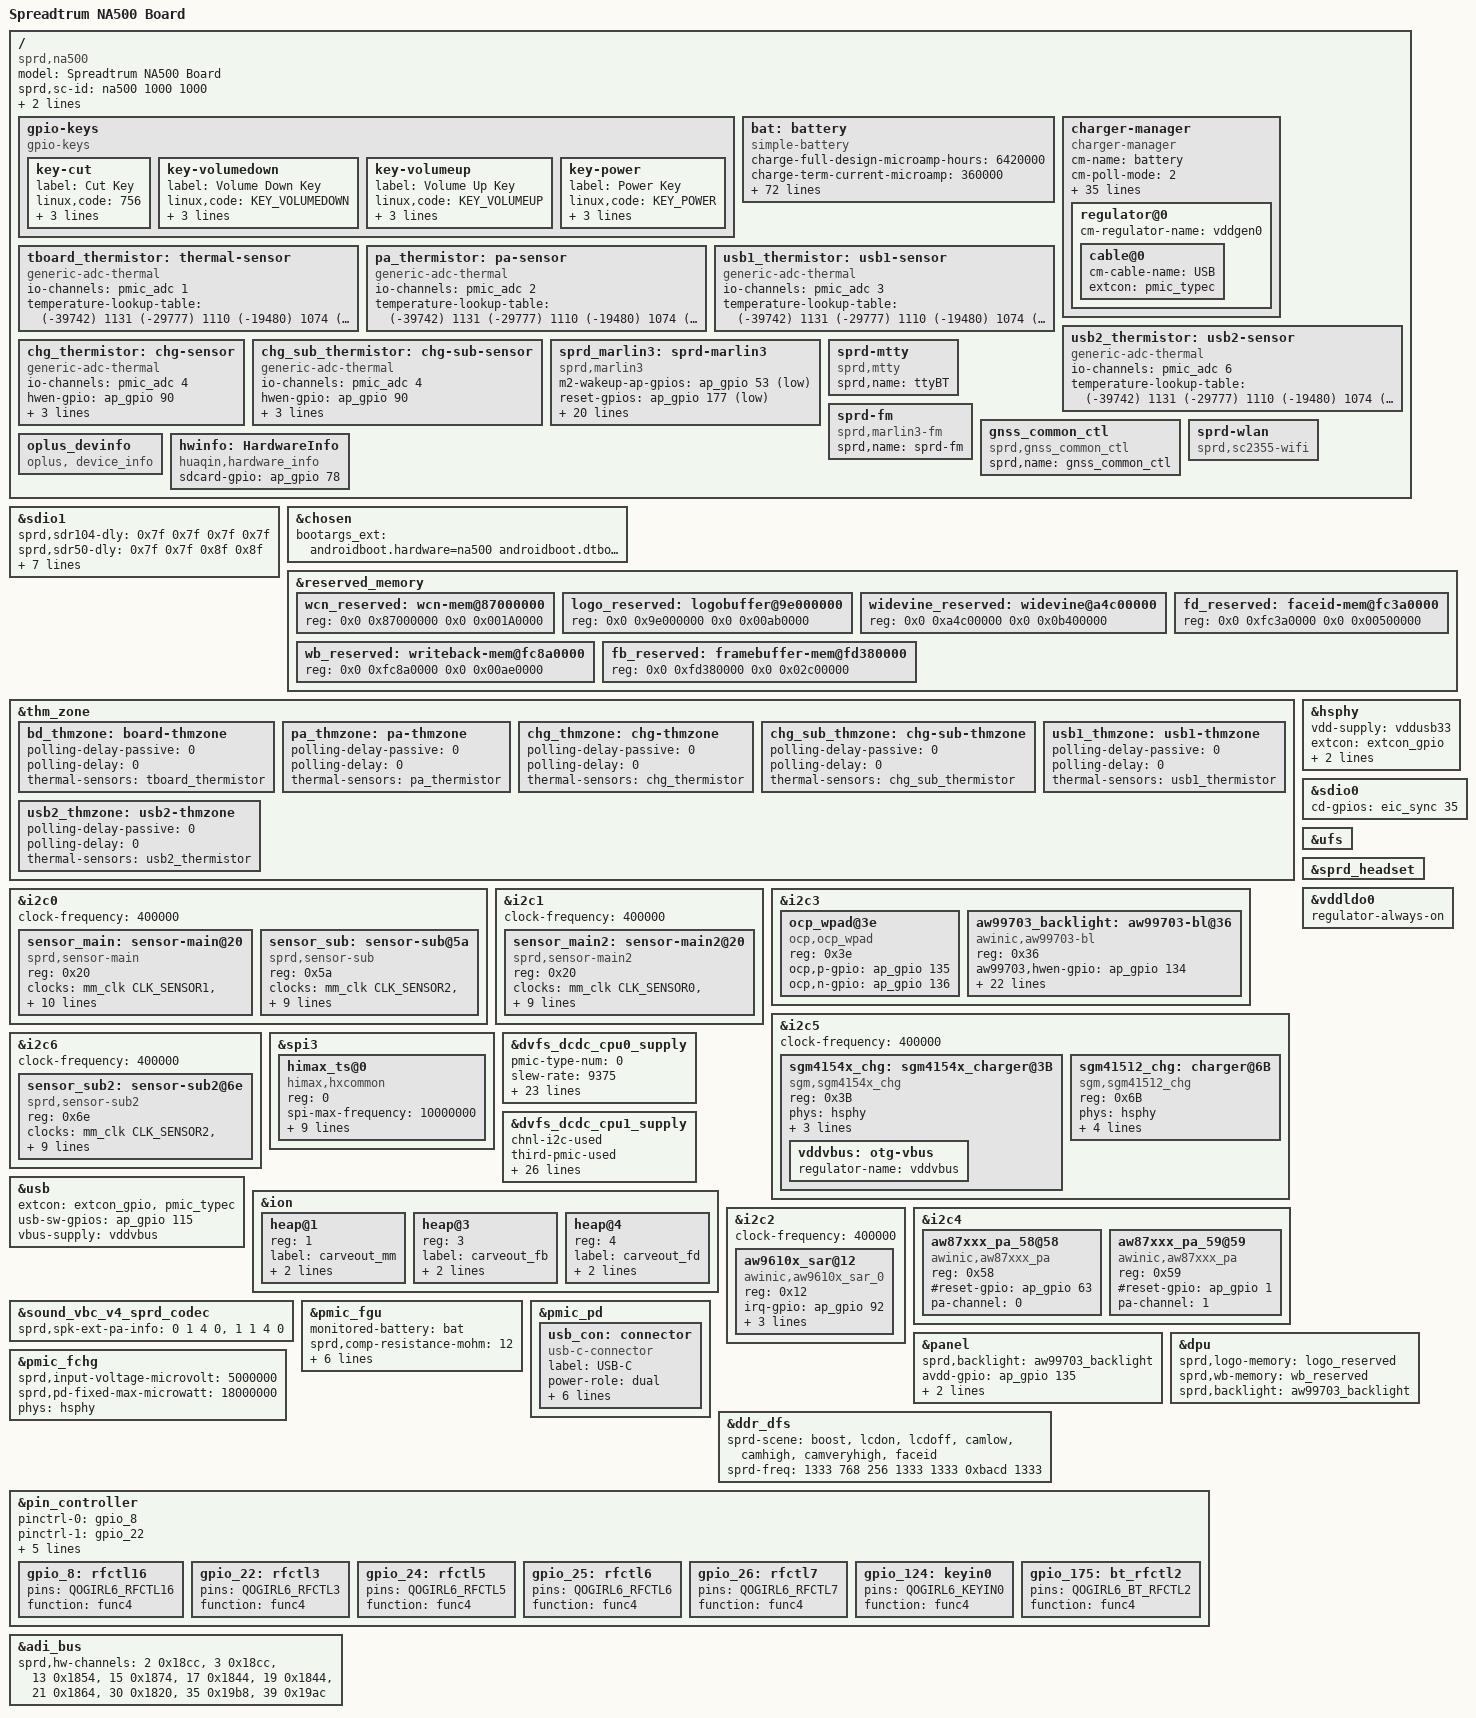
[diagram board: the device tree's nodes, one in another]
/dts-v1/;
/plugin/;
#include <dt-bindings/input/input.h>
#include <dt-bindings/gpio/gpio.h>
#include <dt-bindings/clock/sprd,ums9230-clk.h>
#include <dt-bindings/mfd/sprd,sc2730-regs.h>
#include <dt-bindings/mfd/sprd,sc2730-mask.h>
#include <dt-bindings/usb/pd.h>
/*#include "lcd/lcd_g40396_truly_mipi_fhd.dtsi"*/
#include "lcd/lcd_hx83102e_hsd_fy_mipi_hd.dtsi"
#include "lcd/lcd_ft8201ab_qc_mipi_hd.dtsi"
#include "lcd/lcd_nt36523_lc_mipi_hd.dtsi"
#include "lcd/lcd_hx83102e_hsd_mipi_hd.dtsi"
#include "lcd/lcd_dummy_mipi.dtsi"
//#include "battery/NICKY_REALME_ATL_4V45_5000mah.dtsi"
//#include "battery/NICKY_REALME_GUANYU_4V45_5000mah.dtsi"

/ {

	model = "Spreadtrum NA500 Board";

	compatible = "sprd,na500";

	sprd,sc-id = "na500 1000 1000";
	sprd,dtsi_no = "137005";//2172D
	sprd,board_id = "EVB";

	fragment {
		target-path = "/";
		__overlay__ {
			/*pwm_backlight: sprd_backlight {
				compatible = "sprd,sharkl6-backlight";
				pwms = <&pwms 2 40000>;
				pwm-names = "backlight";
				sprd,max-brightness-level = <924>;
				default-brightness-level = <262>;
				sprd,brightness-scale = <1023>;
				brightness-levels = <
							  0   3   4   5   6   7
					  8   9  10  11  12  13  14  16  17  18
					 19  20  21  22  23  24  25  26  27  28
					 29  31  33  35  37  39  41  43  45  47
					 48  50  52  54  56  58  60  62  64  67
					 69  72  74  76  78  80  82  84  86  88
					 90  92  94  96  98 100 102 104 107 109
					112 114 116 118 120 122 124 126 128 130
					132 134 136 138 140 142 144 147 149 151
					154 156 158 160 162 164 166 168 170 172
					175 178 181 184 187 190 193 196 199 203
					205 208 211 214 217 220 223 226 229 234
					237 240 243 247 250 253 256 259 263 266
					269 270 274 277 280 283 287 290 294 297
					300 303 307 310 314 318 325 329 334 339
					340 343 347 350 354 358 365 369 374 380
					382 385 389 392 396 400 407 411 416 422
					426 430 434 438 442 446 452 457 460 464
					470 474 480 486 492 498 504 508 512 516
					522 527 532 536 540 545 550 555 561 568
					574 579 584 589 594 600 605 610 615 620
					625 630 635 641 647 652 657 662 667 673
					688 694 700 706 712 716 720 725 730 735
					740 746 752 758 764 770 776 782 790 798
					803 810 817 825 832 840 845 850 855 861
					866 872 878 884 890 896 903 911 918 924
				>;
			};
*/
			gpio-keys {
				compatible = "gpio-keys";

				key-cut {
					label = "Cut Key";
					linux,code = <756>;
					gpios = <&ap_gpio 166 GPIO_ACTIVE_HIGH>;
					debounce-interval = <2>;
					wakeup-source;
				};
				
				key-volumedown {
					label = "Volume Down Key";
					linux,code = <KEY_VOLUMEDOWN>;
					gpios = <&ap_gpio 124 GPIO_ACTIVE_LOW>;
					debounce-interval = <2>;
					wakeup-source;
				};

				key-volumeup {
					label = "Volume Up Key";
					linux,code = <KEY_VOLUMEUP>;
					gpios = <&pmic_eic 4 GPIO_ACTIVE_HIGH>;
					debounce-interval = <2>;
					wakeup-source;
				};

				key-power {
					label = "Power Key";
					linux,code = <KEY_POWER>;
					gpios = <&pmic_eic 1 GPIO_ACTIVE_LOW>;
					debounce-interval = <2>;
					wakeup-source;
				};
			};

			bat: battery {
				compatible = "simple-battery";
				charge-full-design-microamp-hours = <6420000>;
				charge-term-current-microamp = <360000>;
				constant_charge_voltage_max_microvolt = <4432000>;
				factory-internal-resistance-micro-ohms = <94000>;
				voltage-min-design-microvolt = <3455000>;
				fast-charge-threshold-microvolt = <4200000>;
				ocv-capacity-celsius = <20>;
				ocv-capacity-table-0 = <4405000 100>, <4342000 95>, <4283000 90>,
							<4222000 85>, <4162000 80>, <4104000 75>,
							<4051000 70>, <4002000 65>, <3957000 60>,
							<3906000 55>, <3860000 50>, <3832000 45>,
							<3811000 40>, <3795000 35>, <3781000 30>,
							<3766000 25>, <3746000 20>, <3723000 15>,
							<3691000 10>, <3678000 5>, <3400000 0>;
				voltage-temp-table = <1404493 650>, <1307739 700>, <1203814 750>,
							<1095466 800>, <986112 850>, <878559 900>,
							<775113 950>, <678461 1000>, <590240 1050>,
							<510773 1100>, <440156 1150>, <378279 1200>,
							<324561 1250>, <278079 1300>, <238259 1350>,
							<204266 1400>, <175208 1450>, <150459 1500>,
							<129410 1550>, <111497 1600>, <96484 1650>,
							<83710 1700>, <72772 1750>, <63417 1800>,
							<55293 1850>, <49524 1900>, <43352 1950>;
				capacity-temp-table = <45 98>, <25 100>, <10 96>, <0 86>, <(-10) 80>;
				resistance-temp-table = <45 77>, <25 100>, <10 156>, <0 1207>, <(-10) 1257>;
				charge-sdp-current-microamp = <600000 500000>;
				charge-dcp-current-microamp = <2090000 2100000>;
				charge-cdp-current-microamp = <1520000 1500000>;
				charge-unknown-current-microamp = <2000000 2000000>;
				charge-fchg-current-microamp = <3000000 2000000>; /*1700 1000*/
				cm-dcp-jeita-temp-table = <900 920 0 4432000 0 4180000>,
					<1000 980 0 4435000 0 4180000>,
					<1050 1030 2090000 4432000 1520000 4180000>,
					<1120 1100 2090000 4432000 1520000 4180000>,
					<1160 1140 2090000 4432000 2090000 4432000>,
					<1450 1430 2090000 4432000 2090000 4432000>,
					<1530 1510 1520000 4128000 1520000 4128000>;
				cm-sdp-jeita-temp-table = <900 920 0 4432000 0 4180000>,
					<1000 980 0 4432000 0 4180000>,
					<1050 1030 600000 4432000 600000 4432000>,
					<1120 1100 600000 4432000 600000 4432000>,
					<1160 1140 600000 4432000 600000 4432000>,
					<1450 1430 600000 4432000 600000 4432000>,
					<1530 1510 600000 4128000 600000 4128000>;
				cm-cdp-jeita-temp-table = <900 920 0 4432000 0 4180000>,
					<1000 980 0 4432000 0 4180000>,
					<1050 1030 1520000 4432000 1520000 4432000>,
					<1120 1100 1520000 4432000 1520000 4432000>,
					<1160 1140 1520000 4432000 1520000 4432000>,
					<1450 1430 1520000 4432000 1520000 4432000>,
					<1530 1510 1520000 4128000 1520000 4128000>;
				cm-unknown-jeita-temp-table = <900 920 0 4432000 0 4180000>,
					<1000 980 0 4432000 0 4180000>,
					<1050 1030 2000000 4432000 1520000 4180000>,
					<1120 1100 2000000 4432000 1520000 4180000>,
					<1160 1140 2000000 4432000 2000000 4432000>,
					<1450 1430 2000000 4432000 2000000 4432000>,
					<1530 1510 1520000 4128000 1520000 4128000>;
				cm-fchg-jeita-temp-table =<900 920 0 4432000 0 4180000>,
					<1000 980 0 4432000 0 4180000>,
					<1050 1030 2565000 4432000 1710000 4180000>,
					<1120 1100 2565000 4432000 1710000 4180000>,
					<1160 1140 3000000 4432000 3000000 4432000>,
					<1450 1430 3000000 4432000 3000000 4432000>,
					<1530 1510 1520000 4128000 1520000 4128000>;
			};

			charger-manager {
				compatible = "charger-manager";
				cm-name = "battery";
				cm-poll-mode = <2>;
				cm-poll-interval = <5000>;
				cm-battery-stat = <2>;

				cm-fullbatt-vchkdrop-ms = <30000>;
				cm-fullbatt-vchkdrop-volt = <100000>;
				cm-fullbatt-voltage = <4410000>;
				cm-fullbatt-current = <360000>;
				cm-fullbatt-capacity = <100>;
				/*Charge pump target charge current*/
				cm-cp-taper-current = <1000000>;

				cm-num-chargers = <2>;
				cm-num-fast-chargers = <1>;
				cm-chargers = "sgm4154x_charger", "sgm41512_charger";
				cm-fast-chargers = "sc2730_fast_charger";
				cm-fuel-gauge = "sc27xx-fgu";

				/* in deci centigrade */
				cm-battery-cold = <200>;
				cm-battery-cold-in-minus;
				cm-battery-hot = <800>;
				cm-battery-temp-diff = <100>;

				/* Allow charging for 25.6hr */
				cm-charging-max = <92160000>;
				/* recovery charging after stop charging 45min */
				cm-discharging-max = <2700000>;

				/* the interval to feed charger watchdog */
				cm-wdt-interval = <60>;

				/* drop voltage in microVolts to allow shutdown */
				cm-shutdown-voltage = <3350000>;

				/* when 99% of the time is exceeded, it will be forced to 100% */
				cm-tickle-time-out = <580>;

				/* how much time to allow capacity change */
				cm-one-cap-time = <30>;
				/* cm-thermal-zone = "board-thmzone"; */
				cm-usb1-zone = "usb1-thmzone";
				cm-usb2-zone = "usb2-thmzone";
				/* when the safe charging voltage is exceeded, stop charging */
				cm-charge-voltage-max = <5800000>;
				cm-fast-charge-voltage-max = <10000000>;
				cm-double-ic-total-limit-current = <2000000>;

				/* drop voltage in microVolts to restart charging */
				cm-charge-voltage-drop = <0>;
				cm-fast-charge-voltage-drop = <700000>;
				cm-flash-charge-voltage-drop = <1000000>;

				//cm-cap-remap-table = <1 2 3>, <2 3 2>, <98 99 2>, <99 100 3>;

				monitored-battery = <&bat>;
				cm-capacity-track;
				
/*odm.hq.bsp.luowenjiang@huaqin.com 2021.11.04 modify for  usb temp protection star*/				
				cm-charge-gpio = <&ap_gpio 113 0>;
/*odm.hq.bsp.luowenjiang@huaqin.com 2021.11.04 modify for  usb temp protection end*/

//				cm-ir-cv-offset-microvolt = <100000>;
//				cm-ir-rc = <10>;
//				cm-ir-us-upper-limit-microvolt = <4500000>;

				regulator@0 {
					cm-regulator-name = "vddgen0";
					cable@0 {
						cm-cable-name = "USB";
						extcon = <&pmic_typec>;
					};
				};
			};

			tboard_thermistor: thermal-sensor {
				compatible = "generic-adc-thermal";
				#thermal-sensor-cells = <0>;
				io-channels = <&pmic_adc 1>;
				io-channel-names = "sensor-channel";
				temperature-lookup-table = <
					(-39742) 1131
					(-29777) 1110
					(-19480) 1074
					(-4679) 983
					10110 838
					24805 654
					44922 413
					54903 316
					64895 238
					74884 178
					84883 133
					94883 100
					104880 75
					114889 57
					124872 43 >;
			};

			pa_thermistor: pa-sensor {
				compatible = "generic-adc-thermal";
				#thermal-sensor-cells = <0>;
				io-channels = <&pmic_adc 2>;
				io-channel-names = "sensor-channel";
				temperature-lookup-table = <
					(-39742) 1131
					(-29777) 1110
					(-19480) 1074
					(-4679) 983
					10110 838
					24805 654
					44922 413
					54903 316
					64895 238
					74884 178
					84883 133
					94883 100
					104880 75
					114889 57
					124872 43 >;
			};
			usb1_thermistor: usb1-sensor {
				compatible = "generic-adc-thermal";
				#thermal-sensor-cells = <0>;
				io-channels = <&pmic_adc 3>;
				io-channel-names = "sensor-channel";
				temperature-lookup-table = <
					(-39742) 1131
					(-29777) 1110
					(-19480) 1074
					(-4679) 983
					10110 838
					24805 654
					44922 413
					54903 316
					64895 238
					74884 178
					84883 133
					94883 100
					104880 75
					114889 57
					124872 43 >;
			};
			usb2_thermistor: usb2-sensor {
				compatible = "generic-adc-thermal";
				#thermal-sensor-cells = <0>;
				io-channels = <&pmic_adc 6>;
				io-channel-names = "sensor-channel";
				temperature-lookup-table = <
					(-39742) 1131
					(-29777) 1110
					(-19480) 1074
					(-4679) 983
					10110 838
					24805 654
					44922 413
					54903 316
					64895 238
					74884 178
					84883 133
					94883 100
					104880 75
					114889 57
					124872 43 >;
			};

			chg_thermistor: chg-sensor {
				compatible = "generic-adc-thermal";
				#thermal-sensor-cells = <0>;
				io-channels = <&pmic_adc 4>;
				io-channel-names = "sensor-channel";
				hwen-gpio = <&ap_gpio 90 0>;
				hwen-channel = <0>;
				temperature-lookup-table = <
					(-39742) 1131
					(-29777) 1110
					(-19480) 1074
					(-4679) 983
					10110 838
					24805 654
					44922 413
					54903 316
					64895 238
					74884 178
					84883 133
					94883 100
					104880 75
					114889 57
					124872 43 >;
			};
			
			chg_sub_thermistor: chg-sub-sensor {
				compatible = "generic-adc-thermal";
				#thermal-sensor-cells = <0>;
				io-channels = <&pmic_adc 4>;
				io-channel-names = "sensor-channel";
				hwen-gpio = <&ap_gpio 90 0>;
				hwen-channel = <1>;
				temperature-lookup-table = <
					(-39742) 1131
					(-29777) 1110
					(-19480) 1074
					(-4679) 983
					10110 838
					24805 654
					44922 413
					54903 316
					64895 238
					74884 178
					84883 133
					94883 100
					104880 75
					114889 57
					124872 43 >;
			};
			sprd_marlin3: sprd-marlin3 {
				compatible = "sprd,marlin3";
				m2-wakeup-ap-gpios = <&ap_gpio 53 GPIO_ACTIVE_LOW>;
				reset-gpios = <&ap_gpio 177 GPIO_ACTIVE_LOW>;
				enable-gpios = <&ap_gpio 116 GPIO_ACTIVE_LOW>;
				m2-to-ap-irq-gpios = <&ap_gpio 52 GPIO_ACTIVE_LOW>;
				avdd12-supply = <&vddwcn>;
				avdd33-supply = <&vddwifipa>;
				dcxo18-supply = <&vddsim2>;

				clock-names = "clk_32k","source","enable";
				clocks = <&aon_clk CLK_AUX2>,
					 <&ext_32k>,
					 <&aonapb_gate CLK_AUX2_EB>;

				reg = <0 0x87000000 0 0x00100000>,
					<0 0x87100000 0 0xA0000>;
				reg-names = "btwf_mem", "gnss_mem";

				sdhci-name = <&sdio1>;
				sprd,btwf-file-name = "/dev/block/by-name/wcnmodem";
				sprd,gnss-file-name = "/dev/block/by-name/gnssmodem";
				adma-tx;
				adma-rx;

				/*
				 * bound parameter:
				 * [0]:addr offset, [1]:mask, [2]:unboundval, [3]:boundval
				 */
				/* avdd12-parent-bound-chip = <REG_ANA_SLP_DCDC_PD_CTRL MASK_ANA_SLP_DCDCGEN1_PD_EN 0x0 MASK_ANA_SLP_DCDCGEN1_PD_EN>; */
				avdd12-bound-wbreq = <REG_ANA_LDO_XTL_EN10 MASK_ANA_LDO_VDDWCN_EXT_XTL3_EN 0x0 MASK_ANA_LDO_VDDWCN_EXT_XTL3_EN>;
				avdd33-bound-wbreq = <REG_ANA_LDO_XTL_EN11 MASK_ANA_LDO_VDDWIFIPA_EXT_XTL3_EN 0x0 MASK_ANA_LDO_VDDWIFIPA_EXT_XTL3_EN>;
			};

			sprd-mtty {
				compatible = "sprd,mtty";
				sprd,name = "ttyBT";
			};

			sprd-fm {
				compatible = "sprd,marlin3-fm";
				sprd,name = "sprd-fm";
			};

			gnss_common_ctl {
				compatible = "sprd,gnss_common_ctl";
				sprd,name = "gnss_common_ctl";
			};

			sprd-wlan{
				compatible = "sprd,sc2355-wifi";
			};
			/*Used to show hardware information for oplus factory mode*/
			oplus_devinfo:oplus_devinfo {
				compatible = "oplus, device_info";
				status = "okay";
			};
			/*Used to show hardware information for hq factory mode*/
			hwinfo:HardwareInfo {
				compatible = "huaqin,hardware_info";
				sdcard-gpio = <&ap_gpio 78 0>;
				status = "okay";
			};
		};
	};
};

&sdio1 {
	sprd,sdr104-dly = <0x7f 0x7f 0x7f 0x7f>;
	sprd,sdr50-dly = <0x7f 0x7f 0x8f 0x8f>;
	sd-uhs-sdr104;
	sd-uhs-sdr50;
	bus-width = <4>;
	sprd,name = "sdio_wifi";
	sprd,sdio-adma;
	no-sd;
	no-mmc;
	status = "okay";
};

&chosen {
	bootargs_ext = "androidboot.hardware=na500 androidboot.dtbo_idx=0";
};

&reserved_memory {
	wcn_reserved: wcn-mem@87000000 {
		reg = <0x0 0x87000000 0x0 0x001A0000>;
	};

	logo_reserved: logobuffer@9e000000{
		reg = <0x0 0x9e000000 0x0 0x00ab0000>;
	};

	widevine_reserved: widevine@a4c00000 {
        reg = <0x0 0xa4c00000 0x0 0x0b400000>;
    };

	fd_reserved: faceid-mem@fc3a0000 {
		reg = <0x0 0xfc3a0000 0x0 0x00500000>;
	};

	wb_reserved: writeback-mem@fc8a0000 {
		reg = <0x0 0xfc8a0000 0x0 0x00ae0000>;
	};

	fb_reserved: framebuffer-mem@fd380000 {
		reg = <0x0 0xfd380000 0x0 0x02c00000>;
	};
};

&thm_zone {
	bd_thmzone: board-thmzone {
		polling-delay-passive = <0>;
		polling-delay = <0>;
		thermal-sensors = <&tboard_thermistor>;
	};

	pa_thmzone: pa-thmzone {
		polling-delay-passive = <0>;
		polling-delay = <0>;
		thermal-sensors = <&pa_thermistor>;
	};

	chg_thmzone: chg-thmzone {
		polling-delay-passive = <0>;
		polling-delay = <0>;
		thermal-sensors = <&chg_thermistor>;
	};
	chg_sub_thmzone: chg-sub-thmzone {
		polling-delay-passive = <0>;
		polling-delay = <0>;
		thermal-sensors = <&chg_sub_thermistor>;
	};

	usb1_thmzone: usb1-thmzone {
		polling-delay-passive = <0>;
		polling-delay = <0>;
		thermal-sensors = <&usb1_thermistor>;
	};
	usb2_thmzone: usb2-thmzone {
		polling-delay-passive = <0>;
		polling-delay = <0>;
		thermal-sensors = <&usb2_thermistor>;
	};
};

&i2c0 {
	status = "okay";
	clock-frequency = <400000>;

	sensor_main: sensor-main@20 {
		compatible = "sprd,sensor-main";
		reg = <0x20>;
		clock-names = "clk_src","sensor_eb",
			"clk_96m","clk_76m8",
			"clk_48m","clk_26m";
		clocks = <&mm_clk CLK_SENSOR1>,<&mm_gate CLK_MM_SENSOR1_EB>,
				<&pll1 CLK_TWPLL_96M>,<&pll1 CLK_TWPLL_76M8>,
				<&pll1 CLK_TWPLL_48M>,<&ext_26m>;
		vddio-supply = <&vddcamio>;
		vddcamd-supply = <&vddcamd0>;
		vddcama-supply = <&vddcama1>;
		//avdd-gpios = <&ap_gpio 129 0>;
		vddcammot-supply = <&vddcammot>;
		reset-gpios = <&ap_gpio 45 0>;
        //power-down-gpios = <&ap_gpio 47 0>;
		sprd,phyid = <0>;
		csi = <&csi0>;
	};

	sensor_sub: sensor-sub@5a {
		compatible = "sprd,sensor-sub";
		reg = <0x5a>;
		clock-names = "clk_src","sensor_eb",
			"clk_96m","clk_76m8",
			"clk_48m","clk_26m";
		clocks = <&mm_clk CLK_SENSOR2>,<&mm_gate CLK_MM_SENSOR2_EB>,
				<&pll1 CLK_TWPLL_96M>,<&pll1 CLK_TWPLL_76M8>,
				<&pll1 CLK_TWPLL_48M>,<&ext_26m>;
		vddio-supply = <&vddcamio>;
		vddcama-supply = <&vddcama0>;
		//avdd-gpios = <&ap_gpio 138 0>;
		vddcamd-supply = <&vddcamd1>;
		reset-gpios = <&ap_gpio 44 0>;
		sprd,phyid = <5>;
		csi = <&csi0>;
	};
};

&i2c1 {
	status = "okay";
	clock-frequency = <400000>;

	sensor_main2: sensor-main2@20 {
		compatible = "sprd,sensor-main2";
		reg = <0x20>;
		clock-names = "clk_src","sensor_eb",
			"clk_96m","clk_76m8",
			"clk_48m","clk_26m";
		clocks = <&mm_clk CLK_SENSOR0>,<&mm_gate CLK_MM_SENSOR0_EB>,
				<&pll1 CLK_TWPLL_96M>,<&pll1 CLK_TWPLL_76M8>,
				<&pll1 CLK_TWPLL_48M>,<&ext_26m>;
		vddio-supply = <&vddcamio>;
		vddcama-supply = <&vddcama1>;
	/*	vddcamd-supply = <&vddcamd0>;*/
	/*	vddcammot-supply = <&vddcammot>;*/
	/*	mot-gpios = <&ap_gpio 113 0>;*/
		reset-gpios = <&ap_gpio 41 0>;
		power-down-gpios = <&ap_gpio 46 0>;
	/*	mipi-switch-en-gpios = <&ap_gpio 55 0>;*/
	/*	mipi-switch-mode-gpios = <&ap_gpio 8 0>;*/
		sprd,phyid = <3>;
		csi = <&csi1>;
	};


};



&i2c3 {
	ocp_wpad@3e {
		compatible = "ocp,ocp_wpad";
		reg = <0x3e>;
		ocp,p-gpio = <&ap_gpio 135 0>;
		ocp,n-gpio = <&ap_gpio 136 0>;
	};


	aw99703_backlight:aw99703-bl@36 {
		compatible = "awinic,aw99703-bl";
		reg = <0x36>;
		aw99703,hwen-gpio = <&ap_gpio 134 0>;
		/* brightness map level 1:256,2:1024,3:2048 */
		aw99703,bl-map = <3>;
		aw99703,using-lsb;
		aw99703,ovp-level = <3>; /* 38V(default) */
		aw99703,ocp-level = <2>; /* 2.7A(default) */
		aw99703,switch-freq = <1>; /* 1000kHz(default) */
		aw99703,auto-freq-high = <0x80>;
		aw99703,auto-freq-low = <0x10>;
		aw99703,bl-fscal-led = <0x13>; /* 20mA(default) */
		aw99703,bl-channel = <3>;
		aw99703,turn-on-ramp = <0x04>; /* 8ms(default) */
		aw99703,turn-off-ramp = <0x04>; /* 8ms(default) */
		aw99703,pwm-trans-dim = <0>; /* 2ms(default) */
		aw99703,i2c-trans-dim = <0>; /* 1us(default) */
		aw99703,pwm-mode = <1>; /* 0 pwm enable,1 PWM disable */
		aw99703,map-type = <0>; /* linear */
		aw99703,work-mode = <1>; /* backlight */
		aw99703,flash-timeout-time = <0x05>; /* 500ms(default) */
		aw99703,flash-current = <0x08>; /* 59.2mA(default) */
		aw99703,efuse-config = <0x1C 0x61 0x61 0x4C 0x2C 0xC0 0x08 0x00 0x01 0xC0 0x00 0x00 0x50>;
				brightness-levels = <
					2
					4 6 8 10 12  14  16  18  20  22  24  26  28  30  32  34  36  38  
					40  42  44  46  48  50  52  54  56  58  
					60  62  64  66  68  71  74  77  80  83  
					86  89  92  95  98  101  104  107  110  113  
					116  120  124  128  134  138  144  148  152  156  
					160  164  168  172  176  180  184  188  192  196  
					200  204  208  214  218  224  228  232  236  240  
					244  248  252  256  260  264  268  272  276  280  
					284  288  294  298  302  308  312  316  320  324  
					328  332  336  340  344  350  356  362  368  374  
					380  386  392  398  406  410  416  422  428  434  
					440  446  452  458  468  474  480  486  494  500  
					506  512  518  526  532  538  540  548  554  560  
					566  574  580  588  594  600  606  614  620  628  
					636  650  658  668  678  680  686  694  700  708  
					716  730  738  748  760  764  770  778  784  792  
					800  814  822  832  844  852  860  868  876  884  
					892  904  914  920  928  940  948  960  972  984  
					996  1008  1016  1024  1032  1044  1054  1064  1072  1080  
					1090  1100  1110  1122  1136  1148  1158  1168  1178  1188  
					1200  1210  1220  1230  1240  1250  1260  1270  1282  1294  
					1304  1314  1324  1334  1346  1376  1388  1400  1412  1424  
					1432  1440  1450  1460  1470  1480  1492  1504  1516  1528  
					1540  1552  1564  1580  1596  1606  1620  1638
				>;
		status = "ok";
	};
};

&i2c5 {
	status = "okay";
	clock-frequency = <400000>;

	sgm4154x_chg: sgm4154x_charger@3B {
		compatible = "sgm,sgm4154x_chg";
		reg = <0x3B>;
		phys = <&hsphy>;
		monitored-battery = <&bat>;
		extcon = <&pmic_typec>;
		pd-extcon-enable;
		vddvbus:otg-vbus {
			regulator-name = "vddvbus";
		};
	};

	sgm41512_chg: charger@6B {
		compatible = "sgm,sgm41512_chg";
		reg = <0x6B>;
		phys = <&hsphy>;
		monitored-battery = <&bat>;
		extcon = <&pmic_typec>;
		enable-gpio = <&ap_gpio 130 GPIO_ACTIVE_LOW>;
		role-slave;
	};

};

&i2c6 {
	status = "okay";
	clock-frequency = <400000>;

	sensor_sub2: sensor-sub2@6e {
		compatible = "sprd,sensor-sub2";
		reg = <0x6e>;
		clock-names = "clk_src","sensor_eb",
			"clk_96m","clk_76m8",
			"clk_48m","clk_26m";
		clocks = <&mm_clk CLK_SENSOR2>,<&mm_gate CLK_MM_SENSOR2_EB>,
			<&pll1 CLK_TWPLL_96M>,<&pll1 CLK_TWPLL_76M8>,
			<&pll1 CLK_TWPLL_48M>,<&ext_26m>;
		vddio-supply = <&vddcamio>;
		avdd-gpios = <&ap_gpio 137 0>;
		vddcamd-supply = <&vddcamd1>;
		vddcammot-supply = <&vddcammot>;
	/*	mot-gpios = <&ap_gpio 112 0>;
		reset-gpios = <&ap_gpio 114 0>;
		power-down-gpios = <&ap_gpio 40 0>;*/
		sprd,phyid = <3>;
		csi = <&csi2>;
	};
};



&spi3 {
	status = "okay";

	himax_ts@0 {
	compatible = "himax,hxcommon","focaltech,fts";
	reg = <0>;
	spi-max-frequency = <10000000>;

	himax,panel-coords = <0 800 0 1340>;
	himax,display-coords = <0 800 0 1340>;
	/*himax,irq-gpio = <&ap_gpio 144 GPIO_ACTIVE_HIGH>;*/
	himax,irq-gpio = <&eic_async 16 GPIO_ACTIVE_HIGH>;
	himax,rst-gpio = <&ap_gpio 145 GPIO_ACTIVE_HIGH>;
	report_type = <1>;
	
	/*focaltech,irq-gpio = <&ap_gpio 144 0>;*/
	focaltech,irq-gpio = <&eic_async 16 GPIO_ACTIVE_HIGH>;
	focaltech,reset-gpio = <&ap_gpio 145 0>;
	focaltech,max-touch-number = <10>;
	focaltech,display-coords =  <0 0 800 1340>;	
	};
};

&dvfs_dcdc_cpu0_supply {
	pmic-type-num = <0>;
	slew-rate = <9375>; /* 9375uV/us */
	top-dvfs-adi-state = <0x70 0 0xf>;
	voltage-grade-num = <8>;
	voltage-grade = <0 0xf0 0xf4 0 0x1ff>,
		<1 0xf0 0xf4 9 0x1ff>,
		<2 0x100 0xf4 18 0x1ff>,
		<3 0x110 0xf8 0 0x1ff>,
		<4 0x120 0xf8 9 0x1ff>,
		<5 0x130 0xf8 18 0x1ff>,
		<6 0x140 0xfc 0 0x1ff>,
		<7 0x140 0xfc 9 0x1ff>;
	voltage-up-delay = <50 0x58 0 0xffff 0x600>,
		<100 0x58 16 0xffff 0xa00>,
		<150 0x54 0 0xffff 0xf00>,
		<200 0x54 16 0xffff 0x1400>,
		<250 0x50 0 0xffff 0x1900>,
		<300 0x50 16 0xffff 0x1e00>,
		<350 0x110 0 0xffff 0x2300>;
	voltage-down-delay = <50 0x64 0 0xffff 0x600>,
		<100 0x64 16 0xffff 0xa00>,
		<150 0x60 0 0xffff 0xf00>,
		<200 0x60 16 0xffff 0x1400>,
		<250 0x5c 0 0xffff 0x1900>,
		<300 0x5c 16 0xffff 0x1e00>,
		<350 0x114 0 0xffff 0x2300>;
	tuning-latency-us = <0>;
	chnl-in-i2c = <0>;
};

&dvfs_dcdc_cpu1_supply {
	chnl-i2c-used;
	third-pmic-used;
	pmic-type-num = <2>;
	slew-rate = <4000>; /* 4000uV/us */
	supply-type-sel = <0x120 0 1>;
	top-dvfs-i2c-state = <0x9c 4 0x1f>;
	voltage-grade-num = <8>;
	voltage-grade = <0 0x8f 0x12c 0 0xff>,
		<1 0x94 0x12c 8 0xff>,
		<2 0x99 0x12c 16 0xff>,
		<3 0x9e 0x12c 24 0xff>,
		<4 0xa3 0x130 0 0xff>,
		<5 0xa8 0x130 8 0xff>,
		<6 0xa8 0x130 16 0xff>,
		<7 0xa8 0x130 24 0xff>;
	voltage-up-delay = <50 0x84 0 0xffff 0x1600>,
		<100 0x84 16 0xffff 0x1a00>,
		<150 0x80 0 0xffff 0x1f00>,
		<200 0x80 16 0xffff 0x2400>,
		<250 0x7c 0 0xffff 0x2900>,
		<300 0x7c 16 0xffff 0x2e00>,
		<350 0x118 0 0xffff 0x3300>;
	voltage-down-delay = <50 0x90 0 0xffff 0x600>,
		<100 0x90 16 0xffff 0xa00>,
		<150 0x8c 0 0xffff 0xf00>,
		<200 0x8c 16 0xffff 0x1400>,
		<250 0x88 0 0xffff 0x1900>,
		<300 0x88 16 0xffff 0x1e00>,
		<350 0x11c 0 0xffff 0x2300>;
	tuning-latency-us = <0>;
	chnl-in-i2c = <1>;
};

&hsphy {
	vdd-supply = <&vddusb33>;
	extcon = <&extcon_gpio>;
	sprd,hsphy-device-eye-pattern = <0x04f3d1c0>;
	sprd,hsphy-host-eye-pattern = <0x04f3d1c0>;
	status = "okay";
};

&usb {
	extcon = <&extcon_gpio>, <&pmic_typec>;
	usb-sw-gpios = <&ap_gpio 115 GPIO_ACTIVE_HIGH>;
	vbus-supply = <&vddvbus>;
	status = "okay";
};

&sdio0 {
	status = "okay";
	cd-gpios = <&eic_sync 35 GPIO_ACTIVE_HIGH>;
};

&ion {
	heap@1 {
		reg = <1>;
		label = "carveout_mm";
		type = <2>;
		memory-region = <&widevine_reserved>;
	};

	heap@3 {
		reg = <3>;
		label = "carveout_fb";
		type = <2>;
		memory-region = <&fb_reserved>;
	};
};

&ufs {
	status = "okay";
};

&i2c2 {
	status = "okay";
	clock-frequency = <400000>;


	 aw9610x_sar@12 {
		compatible = "awinic,aw9610x_sar_0"; /* aw9610x_sar, hjdpending, how many? */
		reg = <0x12>;
		irq-gpio = <&ap_gpio 92 0>;
		aw9610x,using-firmware;
		aw9610x,using-satu;
		sar-num = < 0 >;
		status = "okay";
	};
};


&i2c3 {
	status = "okay";
};

&i2c4 {
	status = "okay";
	
	/* AWINIC AW87XXX Smart K PA */
	aw87xxx_pa_58@58 {
		compatible = "awinic,aw87xxx_pa";
		reg = <0x58>;
		#reset-gpio = <&ap_gpio 63 0>;
		pa-channel = < 0 >;
		status = "okay";
	};

	aw87xxx_pa_59@59 {
		compatible = "awinic,aw87xxx_pa";
		reg = <0x59>;
		#reset-gpio = <&ap_gpio 1 0>;
		pa-channel = < 1 >;
		status = "okay";
	};


/* AWINIC AW87XXX Smart K PA End */

};

&sprd_headset {
	status = "okay";
};

&sound_vbc_v4_sprd_codec {
	status = "okay";
	/*ext_control_type, hook selection, mode, gpio share*/
	/* sprd,spk-ext-pa-info = <0 0 1 0>; */
	sprd,spk-ext-pa-info = <0 1 4 0>, <1 1 4 0>;
	/* sprd,spk-ext-pa-gpio = <&ap_gpio 156 0>; */
};

&vddldo0 {
	regulator-always-on;
};

&pmic_fgu {
	monitored-battery = <&bat>;
	sprd,comp-resistance-mohm = <12>;  /* ntc compensate */
	sprd,calib-resistance-real = <4890>;
	sprd,calib-resistance-spec = <20000>;
	first-calib-voltage = <3580000>;
	first-calib-capacity = <50>;
	bat-detect-gpio = <&ap_gpio 131 0>;
	io-channels = <&pmic_adc 0>, <&pmic_adc 14>;
	io-channel-names = "bat-temp", "charge-vol";
};

&panel {
	sprd,backlight = <&aw99703_backlight>;
	//sprd,backlight = <&pwm_backlight>;

	avdd-gpio = <&ap_gpio 135 GPIO_ACTIVE_HIGH>;
	avee-gpio = <&ap_gpio 136 GPIO_ACTIVE_HIGH>;
	reset-gpio = <&ap_gpio 50 GPIO_ACTIVE_HIGH>;
};

&dpu {
	sprd,logo-memory = <&logo_reserved>;
	sprd,wb-memory = <&wb_reserved>;
	sprd,backlight = <&aw99703_backlight>;
	//sprd,backlight = <&pwm_backlight>;
};

&pmic_fchg {
	sprd,input-voltage-microvolt = <5000000>;
	sprd,pd-fixed-max-microwatt = <18000000>;
	phys = <&hsphy>;
	status = "okay";
};

&pmic_pd {
	status = "okay";
	usb_con: connector {
		compatible = "usb-c-connector";
		label = "USB-C";
		power-role = "dual";
		try-power-role = "sink";
		source-pdos = <PDO_FIXED(5000, 400, PDO_FIXED_USB_COMM)>;
		sink-pdos = <PDO_FIXED(5000, 3000, PDO_FIXED_USB_COMM)
			     PDO_PPS_APDO(3300, 11000, 3000)>;
		op-sink-microwatt = <10000000>;
	};
};

&ddr_dfs {
	  sprd-scene = "boost", "lcdon", "lcdoff", "camlow",
			"camhigh", "camveryhigh", "faceid";
	  sprd-freq = <1333 768 256 1333 1333 0xbacd 1333>;
};

&pin_controller {
	pinctrl-names =
	/* rfctl16 ,rfctl3, rfctl5 */
	"gpio_8", "gpio_22", "gpio_24",
	/* rfctl6, rfctl7, keyin0 */
	"gpio_25", "gpio_26", "gpio_124",
	/* bt_rfctl2 */
	"gpio_175";
	pinctrl-0 = <&gpio_8>;
	pinctrl-1 = <&gpio_22>;
	pinctrl-2 = <&gpio_24>;
	pinctrl-3 = <&gpio_25>;
	pinctrl-4 = <&gpio_26>;
	pinctrl-5 = <&gpio_124>;
	pinctrl-6 = <&gpio_175>;

	gpio_8: rfctl16 {
		pins = "QOGIRL6_RFCTL16";
		function = "func4";
	};

	gpio_22: rfctl3 {
		pins = "QOGIRL6_RFCTL3";
		function = "func4";
	};

	gpio_24: rfctl5 {
		pins = "QOGIRL6_RFCTL5";
		function = "func4";
	};

	gpio_25: rfctl6 {
		pins = "QOGIRL6_RFCTL6";
		function = "func4";
	};

	gpio_26: rfctl7 {
		pins = "QOGIRL6_RFCTL7";
		function = "func4";
	};

	gpio_124: keyin0 {
		pins = "QOGIRL6_KEYIN0";
		function = "func4";
	};

	gpio_175: bt_rfctl2 {
		pins = "QOGIRL6_BT_RFCTL2";
		function = "func4";
	};
};

&ion {
	heap@4 {
		reg = <4>;
		label = "carveout_fd";
		type = <2>;
		memory-region = <&fd_reserved>;
	};
};

&adi_bus {
	sprd,hw-channels = <2 0x18cc>, <3 0x18cc>, <13 0x1854>, <15 0x1874>,
			<17 0x1844>,<19 0x1844>, <21 0x1864>, <30 0x1820>,
			<35 0x19b8>, <39 0x19ac>;
};
